# M365 register map
File version: 0.1
Registers are 32-bit, read-write, reset 0x0 unless marked. A register's access mark holds for its fields unless they carry their own. Offsets are from the block's base; [hi:lo] are bit positions; {n}, {i} and the like mark numbered series.

## UDFS — UDC2 AHB Bridge
Base 0x40008000
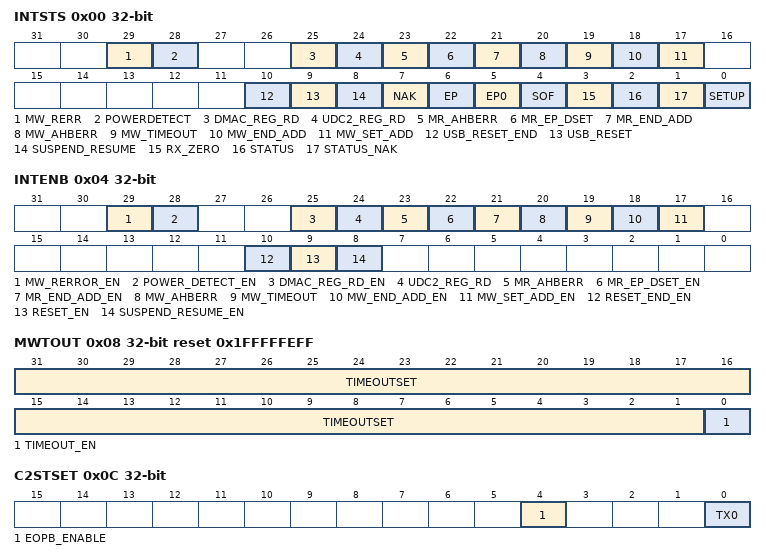
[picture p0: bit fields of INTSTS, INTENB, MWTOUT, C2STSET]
0x00 INTSTS — Interrupt Status Register
  [29] MW_RERR, [28] POWERDETECT, [25] DMAC_REG_RD, [24] UDC2_REG_RD, [23] MR_AHBERR, [22] MR_EP_DSET, [21] MR_END_ADD, [20] MW_AHBERR, [19] MW_TIMEOUT, [18] MW_END_ADD, [17] MW_SET_ADD, [10] USB_RESET_END, [9] USB_RESET, [8] SUSPEND_RESUME, [7] NAK ro, [6] EP ro, [5] EP0 ro, [4] SOF ro, [3] RX_ZERO ro, [2] STATUS ro, [1] STATUS_NAK ro, [0] SETUP ro
0x04 INTENB — Interrupt Enable Register
  [29] MW_RERROR_EN, [28] POWER_DETECT_EN, [25] DMAC_REG_RD_EN, [24] UDC2_REG_RD, [23] MR_AHBERR, [22] MR_EP_DSET_EN, [21] MR_END_ADD_EN, [20] MW_AHBERR, [19] MW_TIMEOUT, [18] MW_END_ADD_EN, [17] MW_SET_ADD_EN, [10] RESET_END_EN, [9] RESET_EN, [8] SUSPEND_RESUME_EN
0x08 MWTOUT reset 0x1FFFFFEFF — Master Write Timeout Register
  [31:1] TIMEOUTSET, [0] TIMEOUT_EN
0x0C C2STSET — UDC2 setting
  [4] EOPB_ENABLE, [0] TX0
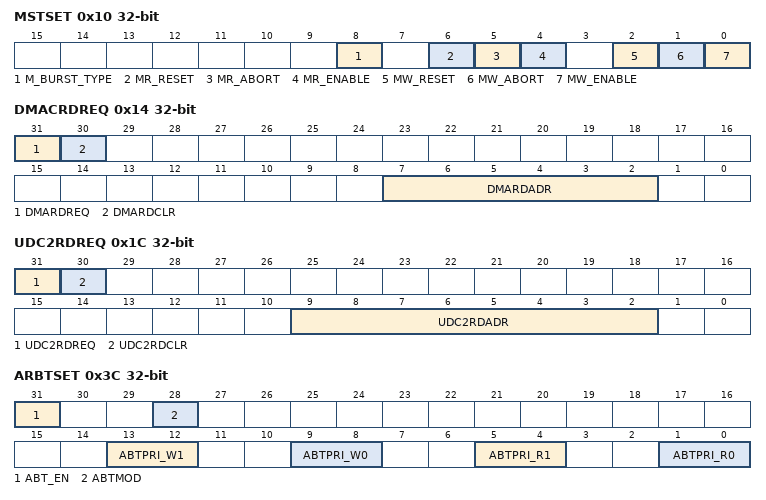
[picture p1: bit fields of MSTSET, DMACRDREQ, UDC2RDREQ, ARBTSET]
0x10 MSTSET — DMAC setting
  [8] M_BURST_TYPE, [6] MR_RESET, [5] MR_ABORT wo, [4] MR_ENABLE, [2] MW_RESET, [1] MW_ABORT wo, [0] MW_ENABLE
0x14 DMACRDREQ — DMAC Read request
  [31] DMARDREQ, [30] DMARDCLR, [7:2] DMARDADR
0x18 DMACRDVL ro — DMAC Read Value
  [31:0] DMARDDATA
0x1C UDC2RDREQ — UDC2 Read Request
  [31] UDC2RDREQ, [30] UDC2RDCLR, [9:2] UDC2RDADR
0x20 UDC2RDVL ro — UDC2 Read Value
  [31:0] UDC2RDATA
0x3C ARBTSET — Arbiter Setting
  [31] ABT_EN, [28] ABTMOD, [13:12] ABTPRI_W1, [9:8] ABTPRI_W0, [5:4] ABTPRI_R1, [1:0] ABTPRI_R0
0x40 MWSADR reset 0xFFFFFFFF — Master Write Start Address
0x44 MWEADR reset 0xFFFFFFFF — Master Write End Address
0x48 MWCADR ro reset 0xFFFFFFFF — Master Write Current Address
0x4C MWAHBADR ro reset 0xFFFFFFFF — Master Write AHB Address
0x50 MRSADR reset 0xFFFFFFFF — Master Read Start Address
0x54 MREADR reset 0xFFFFFFFF — Master Read End Address
0x58 MRCADR ro reset 0xFFFFFFFF — Master Read Current Address
0x5C MRAHBADR ro reset 0xFFFFFFFF — Master Read AHB Address
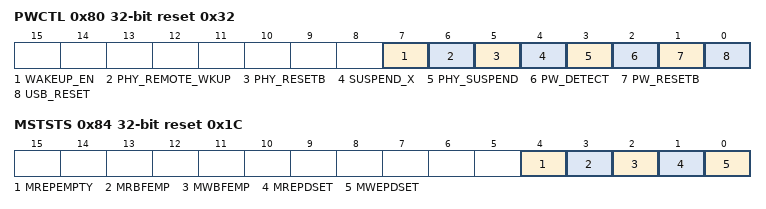
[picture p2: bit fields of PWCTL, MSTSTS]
0x80 PWCTL reset 0x32 — Power Detect Control
  [7] WAKEUP_EN, [6] PHY_REMOTE_WKUP, [5] PHY_RESETB, [4] SUSPEND_X ro, [3] PHY_SUSPEND, [2] PW_DETECT ro, [1] PW_RESETB, [0] USB_RESET ro
0x84 MSTSTS ro reset 0x1C — Master Status
  [4] MREPEMPTY, [3] MRBFEMP, [2] MWBFEMP, [1] MREPDSET, [0] MWEPDSET
0x88 TOUTCNT ro reset 0xFFFFFFFF — Timeout Count
  [31:0] TMOUTCNT

## UDFS2 — UDC2(USB -Spec2.0 Device contoller)
Base 0x40008200
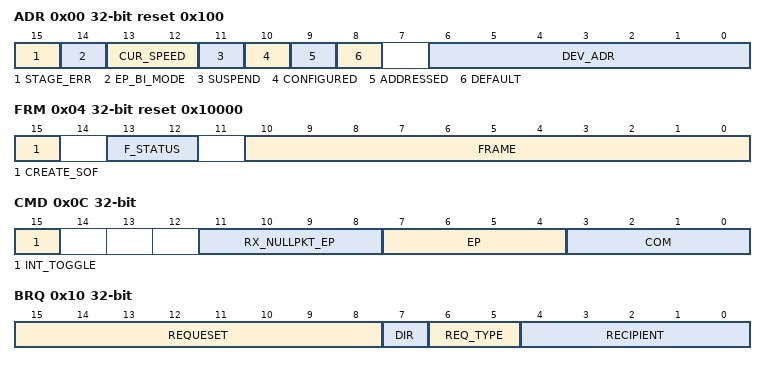
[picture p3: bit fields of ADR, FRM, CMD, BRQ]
0x00 ADR reset 0x100 — UDC2 Address State
  [15] STAGE_ERR, [14] EP_BI_MODE, [13:12] CUR_SPEED ro, [11] SUSPEND ro, [10] CONFIGURED, [9] ADDRESSED, [8] DEFAULT, [6:0] DEV_ADR
0x04 FRM reset 0x10000 — UDC2 Frame
  [15] CREATE_SOF, [13:12] F_STATUS ro, [10:0] FRAME ro
0x0C CMD — UDC2 Command
  [15] INT_TOGGLE, [11:8] RX_NULLPKT_EP ro, [7:4] EP, [3:0] COM
0x10 BRQ ro — UDC2 bRequest-bmRequest Type
  [15:8] REQUESET, [7] DIR, [6:5] REQ_TYPE, [4:0] RECIPIENT
0x14 WVL ro — UDC2 wValue
  [15:0] VALUE
0x18 WIDX ro — UDC2 wIndex
  [15:0] INDEX
0x1C WLGTH ro — UDC2 wLength
  [15:0] LENGTH
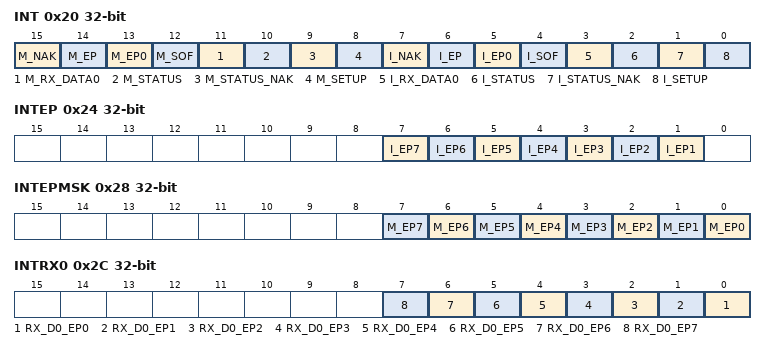
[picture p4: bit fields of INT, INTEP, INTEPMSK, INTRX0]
0x20 INT — UDC2 INT
  [15] M_NAK, [14] M_EP, [13] M_EP0, [12] M_SOF, [11] M_RX_DATA0, [10] M_STATUS, [9] M_STATUS_NAK, [8] M_SETUP, [7] I_NAK, [6] I_EP, [5] I_EP0, [4] I_SOF, [3] I_RX_DATA0, [2] I_STATUS, [1] I_STATUS_NAK, [0] I_SETUP
0x24 INTEP — UDC2 INT_EP
  [n] I_EP{n} (n=1..7)
0x28 INTEPMSK — UDC2 INT_EP_MASK
  [n] M_EP{n} (n=0..7)
0x2C INTRX0 — UDC2 INT RX DATA0
  [n] RX_D0_EP{n} (n=0..7)
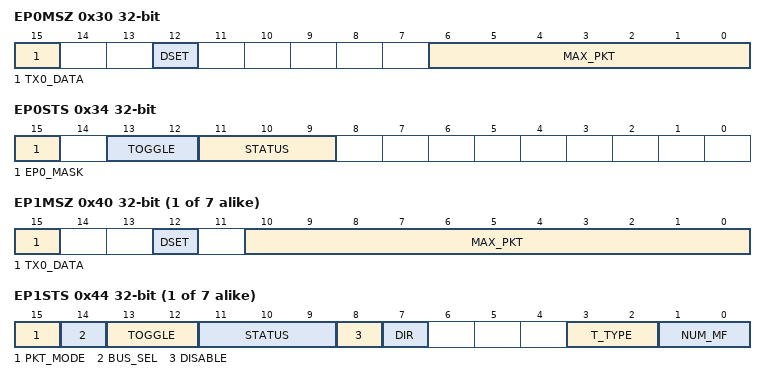
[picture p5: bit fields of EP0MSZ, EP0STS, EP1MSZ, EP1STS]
0x30 EP0MSZ — UDC2 EP0 Max Packet Size
  [15] TX0_DATA ro, [12] DSET ro, [6:0] MAX_PKT
0x34 EP0STS ro — UDC2 EP0 Status
  [15] EP0_MASK, [13:12] TOGGLE, [11:9] STATUS
0x38 EP0DSZ ro — UDC2 EP0 Data Size
  [6:0] SIZE
{0x3C+0x10*i} EP{i}FIFO (i=0..7) — UDC2 EP{i} FIFO
  [15:0] DATA
{0x30+0x10*i} EP{i}MSZ (i=1..7) — UDC2 EP{i} Max Packet Size
  [15] TX0_DATA ro, [12] DSET ro, [10:0] MAX_PKT
{0x34+0x10*i} EP{i}STS (i=1..7) — UDC2 EP{i} Status
  [15] PKT_MODE, [14] BUS_SEL, [13:12] TOGGLE ro, [11:9] STATUS ro, [8] DISABLE ro, [7] DIR, [3:2] T_TYPE, [1:0] NUM_MF
{0x38+0x10*i} EP{i}DSZ ro (i=1..7) — UDC2 EP{i} Data Size
  [10:0] SIZE
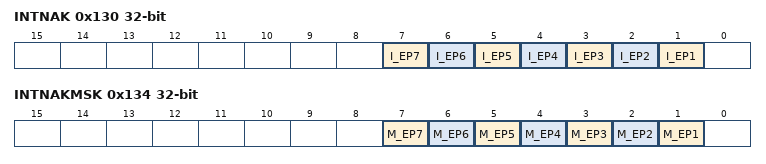
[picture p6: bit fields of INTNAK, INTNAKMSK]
0x130 INTNAK — UDC2 INT NAK
  [n] I_EP{n} (n=1..7)
0x134 INTNAKMSK — UDC2 INT NAK MASK
  [n] M_EP{n} (n=1..7)
